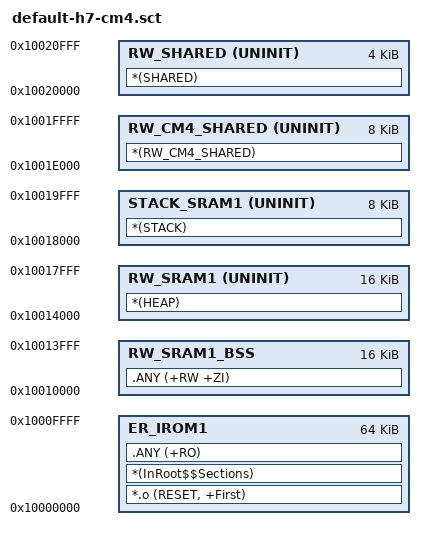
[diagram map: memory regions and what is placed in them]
; *************************************************************
; *** Scatter-Loading Description File generated by uVision ***
; *************************************************************

LR_IROM1 0x10000000 0x00010000  {    ; load region size_region
  ER_IROM1 0x10000000 0x00010000  {  ; load address = execution address
   *.o (RESET, +First)
   *(InRoot$$Sections)
   .ANY (+RO)
  }
  RW_SRAM1_BSS 0x10010000 0x00004000  {  ; SRAM1
   .ANY (+RW +ZI)
  }
  RW_SRAM1 0x10014000 UNINIT 0x00004000  {  ; SRAM1
   *(HEAP)
  }
  STACK_SRAM1 0x10018000 UNINIT 0x00002000  {  ; SRAM1
   *(STACK)
  }
  RW_CM4_SHARED 0x1001e000 UNINIT 0x00002000  { ;SRAM1
   *(RW_CM4_SHARED)
  }
  RW_SHARED 0x10020000 UNINIT 0x00001000  { ;SRAM1
   *(SHARED)
  }
}
;0x38801000 - 0x3FFFFFFF Reserved
;0x38800000 - 0x38800FFF Backup SRAM
;0x38010000 - 0x387FFFFF Reserved
;0x38000000 - 0x3800FFFF SRAM4
;0x30048000 - 0x37FFFFFF Reserved
;0x30040000 - 0x30047FFF SRAM3
;0x30020000 - 0x3003FFFF SRAM2
;0x30000000 - 0x3001FFFF SRAM1
;0x24080000 - 0x2FFFFFFF Reserved
;0x24000000 - 0x2407FFFF AXI SRAM
;0x20020000 - 0x23FFFFFF
;0x20000000 - 0x2001FFFF DTCM (Only M7 core)
;0x00000000 - 0x0000FFFF M7 - ITCM; M4 - VTOR REMAP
